# FM33FG0XXA register map
File version: 1.0
CPU: SC000 r1p0, little endian, MPU, no FPU, 3 interrupt priority bits
Registers are 32-bit, read-only, reset 0x0 unless marked. A register's access mark holds for its fields unless they carry their own. Offsets are from the block's base; [hi:lo] are bit positions; {n}, {i} and the like mark numbered series.

## ATIM — ATIM module information
Base 0x40013000
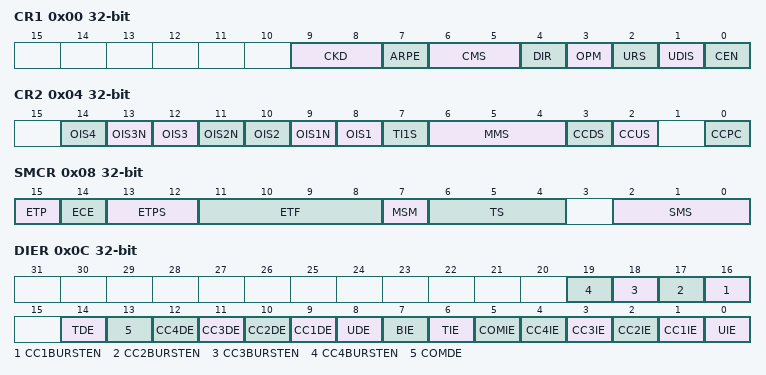
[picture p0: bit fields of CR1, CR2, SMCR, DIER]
0x00 CR1 rw — ATIM Control Register1
  [9:8] CKD — CKD field description
  [7] ARPE — ARPE field description
  [6:5] CMS — CMS field description
  [4] DIR — DIR field description
  [3] OPM — OPM field description
  [2] URS — URS field description
  [1] UDIS — UDIS field description
  [0] CEN — CEN field description
0x04 CR2 rw — ATIM Control Register2
  [2n+6] OIS{n} (n=1..4) — OIS{n} field description
  [13] OIS3N — OIS3N field description
  [11] OIS2N — OIS2N field description
  [9] OIS1N — OIS1N field description
  [7] TI1S — TI1S field description
  [6:4] MMS — MMS field description
  [3] CCDS — CCDS field description
  [2] CCUS — CCUS field description
  [0] CCPC — CCPC field description
0x08 SMCR rw — ATIM Slave Mode Control Register
  [15] ETP — ETP field description
  [14] ECE — ECE field description
  [13:12] ETPS — ETPS field description
  [11:8] ETF — ETF field description
  [7] MSM — MSM field description
  [6:4] TS — TS field description
  [2:0] SMS — SMS field description
0x0C DIER rw — ATIM DMA and Interrupt Enable Register
  [n+15] CC{n}BURSTEN (n=1..4) — CC{n}BURSTEN field description
  [14] TDE — TDE field description
  [13] COMDE — COMDE field description
  [n+8] CC{n}DE (n=1..4) — CC{n}DE field description
  [8] UDE — UDE field description
  [7] BIE — BIE field description
  [6] TIE — TIE field description
  [5] COMIE — COMIE field description
  [n] CC{n}IE (n=1..4) — CC{n}IE field description
  [0] UIE — UIE field description
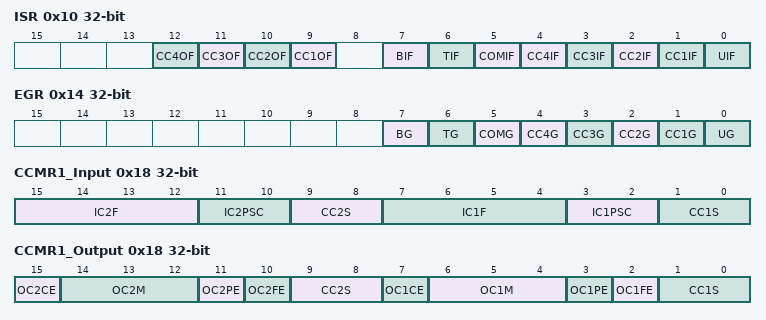
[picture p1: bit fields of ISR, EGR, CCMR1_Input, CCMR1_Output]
0x10 ISR rw — ATIM Interrupt Status Register
  [n+8] CC{n}OF (n=1..4) — CC{n}OF field description
  [7] BIF — BIF field description
  [6] TIF — TIF field description
  [5] COMIF — COMIF field description
  [n] CC{n}IF (n=1..4) — CC{n}IF field description
  [0] UIF — UIF field description
0x14 EGR wo — ATIM Event Generation Register
  [7] BG — BG field description
  [6] TG — TG field description
  [5] COMG — COMG field description
  [n] CC{n}G (n=1..4) — CC{n}G field description
  [0] UG — UG field description
0x18 CCMR1_Input rw — ATIM Capture/Compare Mode Register1
  [15:12] IC2F — IC2F field description
  [11:10] IC2PSC — IC2PSC field description
  [9:8] CC2S — CC2S field description
  [7:4] IC1F — IC1F field description
  [3:2] IC1PSC — IC1PSC field description
  [1:0] CC1S — CC1S field description
0x18 CCMR1_Output rw (alternate view of CCMR1_Input) — ATIM Capture/Compare Mode Register1
  [15] OC2CE — OC2CE field description
  [14:12] OC2M — OC2M field description
  [11] OC2PE — OC2PE field description
  [10] OC2FE — OC2FE field description
  [9:8] CC2S — CC2S field description
  [7] OC1CE — OC1CE field description
  [6:4] OC1M — OC1M field description
  [3] OC1PE — OC1PE field description
  [2] OC1FE — OC1FE field description
  [1:0] CC1S — CC1S field description
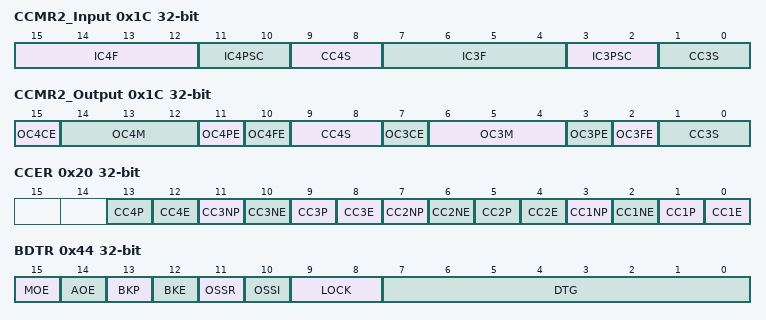
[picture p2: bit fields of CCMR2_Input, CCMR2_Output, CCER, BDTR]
0x1C CCMR2_Input rw — ATIM Capture/Compare Mode Register2
  [15:12] IC4F — IC4F field description
  [11:10] IC4PSC — IC4PSC field description
  [9:8] CC4S — CC4S field description
  [7:4] IC3F — IC3F field description
  [3:2] IC3PSC — IC3PSC field description
  [1:0] CC3S — CC3S field description
0x1C CCMR2_Output rw (alternate view of CCMR2_Input) — ATIM Capture/Compare Mode Register2
  [15] OC4CE — OC4CE field description
  [14:12] OC4M — OC4M field description
  [11] OC4PE — OC4PE field description
  [10] OC4FE — OC4FE field description
  [9:8] CC4S — CC4S field description
  [7] OC3CE — OC3CE field description
  [6:4] OC3M — OC3M field description
  [3] OC3PE — OC3PE field description
  [2] OC3FE — OC3FE field description
  [1:0] CC3S — CC3S field description
0x20 CCER rw — ATIM Capture/Compare Enable Register
  [4n-3] CC{n}P (n=1..4) — CC{n}P field description
  [4n-4] CC{n}E (n=1..4) — CC{n}E field description
  [11] CC3NP — CC3NP field description
  [10] CC3NE — CC3NE field description
  [7] CC2NP — CC2NP field description
  [6] CC2NE — CC2NE field description
  [3] CC1NP — CC1NP field description
  [2] CC1NE — CC1NE field description
0x24 CNT rw — ATIM Counter Register
  [15:0] CNT — CNT field description
0x28 PSC rw — ATIM Prescaler Register
  [15:0] PSC — PSC field description
0x2C ARR rw — ATIM Auto-Reload Register
  [15:0] ARR — ARR field description
0x30 RCR rw — ATIM Repetition Counter Register
  [7:0] REP — REP field description
{0x30+4i} CCR{i} rw (i=1..4) — ATIM Capture/Compare Register{i}
  [15:0] CCR{i} — CCR{i} field description
0x44 BDTR rw — ATIM Break and Deadtime Register
  [15] MOE — MOE field description
  [14] AOE — AOE field description
  [13] BKP — BKP field description
  [12] BKE — BKE field description
  [11] OSSR — OSSR field description
  [10] OSSI — OSSI field description
  [9:8] LOCK — LOCK field description
  [7:0] DTG — DTG field description
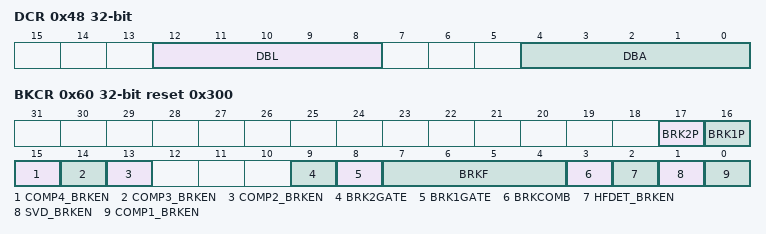
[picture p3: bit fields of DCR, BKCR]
0x48 DCR rw — ATIM DMA Control Register
  [12:8] DBL — DBL field description
  [4:0] DBA — DBA field description
0x4C DMAR rw — ATIM DMA Access Register
  [31:0] DMAR — DMAR field description
0x60 BKCR rw reset 0x300 — ATIM Break Control Register
  [17] BRK2P — BRK2P field description
  [16] BRK1P — BRK1P field description
  [15] COMP4_BRKEN — COMP4_BRKEN field description
  [14] COMP3_BRKEN — COMP3_BRKEN field description
  [13] COMP2_BRKEN — COMP2_BRKEN field description
  [9] BRK2GATE — BRK2GATE field description
  [8] BRK1GATE — BRK1GATE field description
  [7:4] BRKF — BRKF field description
  [3] BRKCOMB — BRKCOMB field description
  [2] HFDET_BRKEN — HFDET_BRKEN field description
  [1] SVD_BRKEN — SVD_BRKEN field description
  [0] COMP1_BRKEN — COMP1_BRKEN field description

## GPTIM0 — GPTIM0 module information
Base 0x40014C00
Same registers: GPTIM1 0x40016400, GPTIM2 0x40018000
Registers as ATIM (with ATIM read as GPTIM0), without RCR, BDTR, BKCR; these are added or differ:
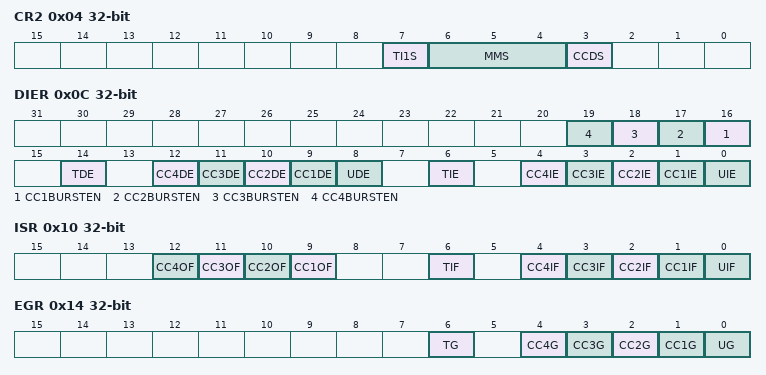
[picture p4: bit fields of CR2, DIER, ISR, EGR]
0x04 CR2 rw — GPTIM0 Control Register2
  [7] TI1S — TI1S field description
  [6:4] MMS — MMS field description
  [3] CCDS — CCDS field description
0x0C DIER rw — GPTIM0 DMA and Interrupt Enable Register
  [n+15] CC{n}BURSTEN (n=1..4) — CC{n}BURSTEN field description
  [14] TDE — TDE field description
  [n+8] CC{n}DE (n=1..4) — CC{n}DE field description
  [8] UDE — UDE field description
  [6] TIE — TIE field description
  [n] CC{n}IE (n=1..4) — CC{n}IE field description
  [0] UIE — UIE field description
0x10 ISR rw — GPTIM0 Interrupt Status Register
  [n+8] CC{n}OF (n=1..4) — CC{n}OF field description
  [6] TIF — TIF field description
  [n] CC{n}IF (n=1..4) — CC{n}IF field description
  [0] UIF — UIF field description
0x14 EGR wo — GPTIM0 Event Generation Register
  [6] TG — TG field description
  [n] CC{n}G (n=1..4) — CC{n}G field description
  [0] UG — UG field description
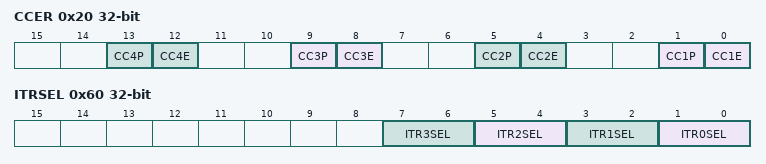
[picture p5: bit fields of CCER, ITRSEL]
0x20 CCER rw — GPTIM0 Capture/Compare Enable Register
  [4n-3] CC{n}P (n=1..4) — CC{n}P field description
  [4n-4] CC{n}E (n=1..4) — CC{n}E field description
0x2C ARR rw reset 0xFFFF — GPTIM0 Auto-Reload Register
  [15:0] ARR — ARR field description
0x4C DMAR rw — GPTIM0 DMA access Register
  [15:0] DMAR — DMAR field description
0x60 ITRSEL rw — GPTIM0 Internal Trigger Select Register
  [2n+1:2n] ITR{n}SEL (n=0..3) — ITR{n}SEL field description
